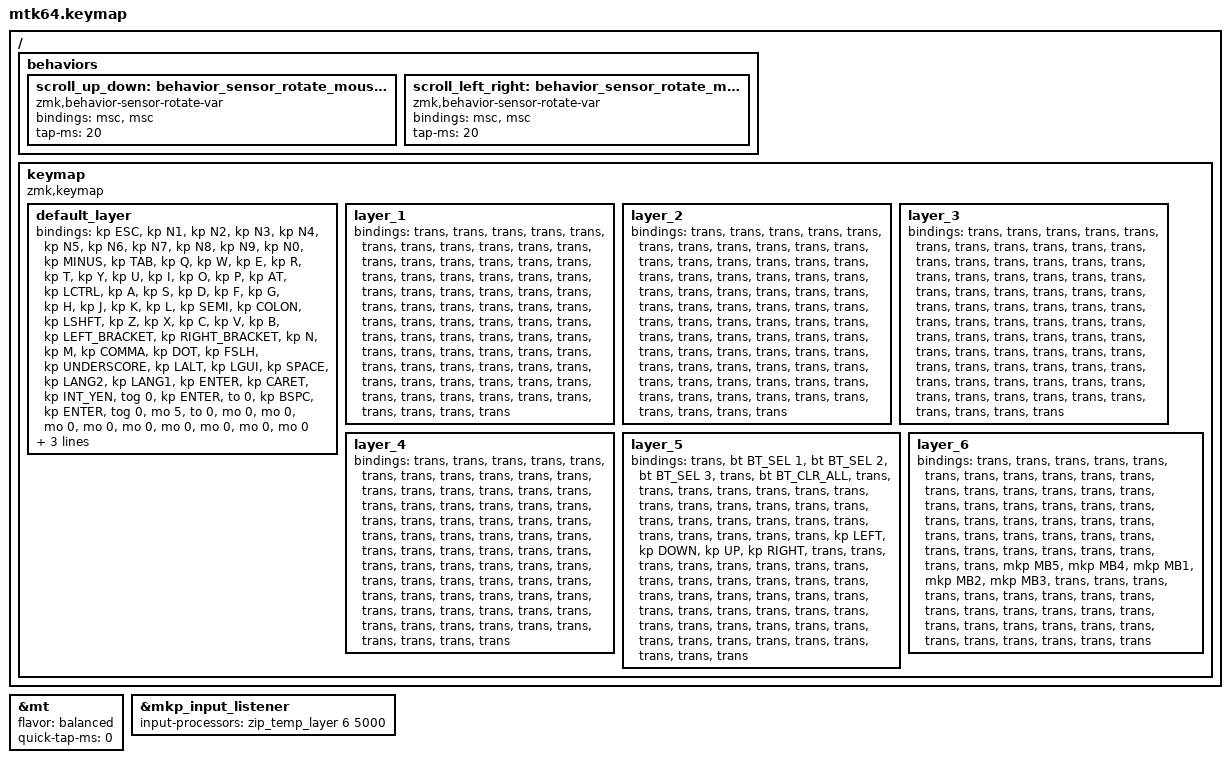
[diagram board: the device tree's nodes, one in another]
#include <input/processors.dtsi>
#include <behaviors.dtsi>
#include <dt-bindings/zmk/bt.h>
#include <dt-bindings/zmk/keys.h>
#include <dt-bindings/zmk/pointing.h>
#include "keycode_japanese.h"

// スクロール量の設定

#define ZMK_POINTING_DEFAULT_SCRL_VAL 100

&mt {
    flavor = "balanced";
    quick-tap-ms = <0>;
};

&mkp_input_listener { input-processors = <&zip_temp_layer 6 5000>; };

/ {
    behaviors {
        // 垂直スクロール用のbehaviorの設定

        scroll_up_down: behavior_sensor_rotate_mouse_wheel_up_down {
            compatible = "zmk,behavior-sensor-rotate-var";
            #sensor-binding-cells = <2>;
            bindings = <&msc>, <&msc>;

            tap-ms = <20>; // スクロールのタップ時間
        };

        // 水平スクロール用のbehaviorの設定

        scroll_left_right: behavior_sensor_rotate_mouse_wheel_left_right {
            compatible = "zmk,behavior-sensor-rotate-var";
            #sensor-binding-cells = <2>;
            bindings = <&msc>, <&msc>;

            tap-ms = <20>; // スクロールのタップ時間
        };
    };
};

/ {
    keymap {
        compatible = "zmk,keymap";

        default_layer {
            bindings = <
&kp ESC  &kp N1  &kp N2  &kp N3  &kp N4  &kp N5  &kp N6  &kp N7  &kp N8  &kp N9  &kp N0  &kp MINUS  &kp TAB  &kp Q  &kp W  &kp E  &kp R  &kp T  &kp Y  &kp U  &kp I  &kp O  &kp P  &kp AT  &kp LCTRL  &kp A  &kp S  &kp D  &kp F  &kp G  &kp H  &kp J  &kp K  &kp L  &kp SEMI  &kp COLON  &kp LSHFT  &kp Z  &kp X  &kp C  &kp V  &kp B  &kp LEFT_BRACKET  &kp RIGHT_BRACKET  &kp N  &kp M  &kp COMMA  &kp DOT  &kp FSLH  &kp UNDERSCORE  &kp LALT  &kp LGUI  &kp SPACE  &kp LANG2  &kp LANG1  &kp ENTER  &kp CARET  &kp INT_YEN  &tog 0  &kp ENTER  &to 0  &kp BSPC  &kp ENTER  &tog 0  &mo 5  &to 0  &mo 0  &mo 0  &mo 0  &mo 0  &mo 0  &mo 0  &mo 0  &mo 0  &mo 0
            >;

            sensor-bindings = <
                &inc_dec_kp LEFT_ARROW RIGHT_ARROW
                &inc_dec_kp UP_ARROW   DOWN_ARROW
            >;
        };

        layer_1 {
            bindings = <
&trans  &trans  &trans  &trans  &trans  &trans  &trans  &trans  &trans  &trans  &trans  &trans  &trans  &trans  &trans  &trans  &trans  &trans  &trans  &trans  &trans  &trans  &trans  &trans  &trans  &trans  &trans  &trans  &trans  &trans  &trans  &trans  &trans  &trans  &trans  &trans  &trans  &trans  &trans  &trans  &trans  &trans  &trans  &trans  &trans  &trans  &trans  &trans  &trans  &trans  &trans  &trans  &trans  &trans  &trans  &trans  &trans  &trans  &trans  &trans  &trans  &trans  &trans  &trans  &trans  &trans  &trans  &trans  &trans  &trans  &trans  &trans  &trans  &trans  &trans
            >;
        };

        layer_2 {
            bindings = <
&trans  &trans  &trans  &trans  &trans  &trans  &trans  &trans  &trans  &trans  &trans  &trans  &trans  &trans  &trans  &trans  &trans  &trans  &trans  &trans  &trans  &trans  &trans  &trans  &trans  &trans  &trans  &trans  &trans  &trans  &trans  &trans  &trans  &trans  &trans  &trans  &trans  &trans  &trans  &trans  &trans  &trans  &trans  &trans  &trans  &trans  &trans  &trans  &trans  &trans  &trans  &trans  &trans  &trans  &trans  &trans  &trans  &trans  &trans  &trans  &trans  &trans  &trans  &trans  &trans  &trans  &trans  &trans  &trans  &trans  &trans  &trans  &trans  &trans  &trans
            >;
        };

        layer_3 {
            bindings = <
&trans  &trans  &trans  &trans  &trans  &trans  &trans  &trans  &trans  &trans  &trans  &trans  &trans  &trans  &trans  &trans  &trans  &trans  &trans  &trans  &trans  &trans  &trans  &trans  &trans  &trans  &trans  &trans  &trans  &trans  &trans  &trans  &trans  &trans  &trans  &trans  &trans  &trans  &trans  &trans  &trans  &trans  &trans  &trans  &trans  &trans  &trans  &trans  &trans  &trans  &trans  &trans  &trans  &trans  &trans  &trans  &trans  &trans  &trans  &trans  &trans  &trans  &trans  &trans  &trans  &trans  &trans  &trans  &trans  &trans  &trans  &trans  &trans  &trans  &trans
            >;
        };

        layer_4 {
            bindings = <
&trans  &trans  &trans  &trans  &trans  &trans  &trans  &trans  &trans  &trans  &trans  &trans  &trans  &trans  &trans  &trans  &trans  &trans  &trans  &trans  &trans  &trans  &trans  &trans  &trans  &trans  &trans  &trans  &trans  &trans  &trans  &trans  &trans  &trans  &trans  &trans  &trans  &trans  &trans  &trans  &trans  &trans  &trans  &trans  &trans  &trans  &trans  &trans  &trans  &trans  &trans  &trans  &trans  &trans  &trans  &trans  &trans  &trans  &trans  &trans  &trans  &trans  &trans  &trans  &trans  &trans  &trans  &trans  &trans  &trans  &trans  &trans  &trans  &trans  &trans
            >;
        };

        layer_5 {
            bindings = <
&trans  &bt BT_SEL 1  &bt BT_SEL 2  &bt BT_SEL 3  &trans  &bt BT_CLR_ALL  &trans  &trans  &trans  &trans  &trans  &trans  &trans  &trans  &trans  &trans  &trans  &trans  &trans  &trans  &trans  &trans  &trans  &trans  &trans  &trans  &trans  &trans  &trans  &trans  &kp LEFT  &kp DOWN  &kp UP  &kp RIGHT  &trans  &trans  &trans  &trans  &trans  &trans  &trans  &trans  &trans  &trans  &trans  &trans  &trans  &trans  &trans  &trans  &trans  &trans  &trans  &trans  &trans  &trans  &trans  &trans  &trans  &trans  &trans  &trans  &trans  &trans  &trans  &trans  &trans  &trans  &trans  &trans  &trans  &trans  &trans  &trans  &trans
            >;
        };

        layer_6 {
            bindings = <
&trans  &trans  &trans  &trans  &trans  &trans  &trans  &trans  &trans  &trans  &trans  &trans  &trans  &trans  &trans  &trans  &trans  &trans  &trans  &trans  &trans  &trans  &trans  &trans  &trans  &trans  &trans  &trans  &trans  &trans  &trans  &trans  &trans  &trans  &trans  &trans  &trans  &trans  &trans  &trans  &trans  &trans  &trans  &mkp MB5  &mkp MB4  &mkp MB1  &mkp MB2  &mkp MB3  &trans  &trans  &trans  &trans  &trans  &trans  &trans  &trans  &trans  &trans  &trans  &trans  &trans  &trans  &trans  &trans  &trans  &trans  &trans  &trans  &trans  &trans  &trans  &trans  &trans  &trans  &trans
            >;
        };
    };
};
